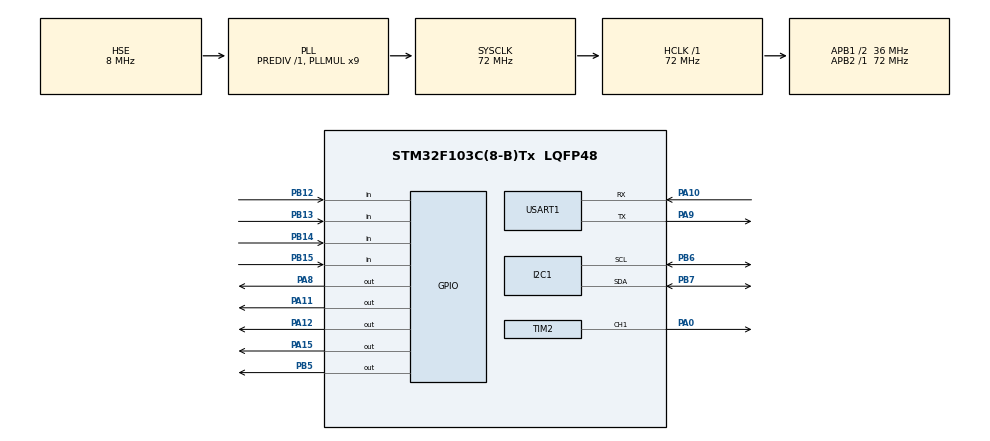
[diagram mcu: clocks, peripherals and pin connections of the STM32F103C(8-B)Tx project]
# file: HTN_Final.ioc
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FREERTOS.Tasks01=defaultTask,24,128,StartDefaultTask,Default,NULL,Dynamic,NULL,NULL
FREERTOS.configUSE_NEWLIB_REENTRANT=1
Mcu.Family=STM32F1
Mcu.Name=STM32F103C(8-B)Tx
Mcu.Package=LQFP48
NVIC.PriorityGroup=NVIC_PRIORITYGROUP_4
NVIC.TIM4_IRQn=true\:15\:0\:false\:false\:true\:false\:false\:true\:true
NVIC.TimeBase=TIM4_IRQn
NVIC.TimeBaseIP=TIM4
NVIC.USART1_IRQn=true\:5\:0\:false\:false\:true\:true\:true\:true\:true
PA0-WKUP.Signal=S_TIM2_CH1_ETR
PA10.Mode=Asynchronous
PA10.Signal=USART1_RX
PA11.Signal=GPIO_Output
PA12.Signal=GPIO_Output
PA13.Mode=Serial_Wire
PA13.Signal=SYS_JTMS-SWDIO
PA14.Mode=Serial_Wire
PA14.Signal=SYS_JTCK-SWCLK
PA15.Signal=GPIO_Output
PA8.Signal=GPIO_Output
PA9.Mode=Asynchronous
PA9.Signal=USART1_TX
PB12.GPIO_PuPd=GPIO_PULLUP
PB12.Signal=GPIO_Input
PB13.GPIO_PuPd=GPIO_PULLUP
PB13.Signal=GPIO_Input
PB14.GPIO_PuPd=GPIO_PULLUP
PB14.Signal=GPIO_Input
PB15.GPIO_PuPd=GPIO_PULLUP
PB15.Signal=GPIO_Input
PB5.Signal=GPIO_Output
PB6.Mode=I2C
PB6.Signal=I2C1_SCL
PB7.Mode=I2C
PB7.Signal=I2C1_SDA
PD0-OSC_IN.Mode=HSE-External-Oscillator
PD0-OSC_IN.Signal=RCC_OSC_IN
PD1-OSC_OUT.Mode=HSE-External-Oscillator
PD1-OSC_OUT.Signal=RCC_OSC_OUT
ProjectManager.HeapSize=0x200
ProjectManager.StackSize=0x400
ProjectManager.TargetToolchain=STM32CubeIDE
RCC.AHBFreq_Value=72000000
RCC.APB1CLKDivider=RCC_HCLK_DIV2
RCC.APB1Freq_Value=36000000
RCC.APB1TimFreq_Value=72000000
RCC.APB2Freq_Value=72000000
RCC.APB2TimFreq_Value=72000000
RCC.HCLKFreq_Value=72000000
RCC.PLLMUL=RCC_PLL_MUL9
RCC.PLLSourceVirtual=RCC_PLLSOURCE_HSE
RCC.SYSCLKFreq_VALUE=72000000
RCC.SYSCLKSource=RCC_SYSCLKSOURCE_PLLCLK
RCC.USBFreq_Value=72000000
SH.S_TIM2_CH1_ETR.0=TIM2_CH1,PWM Generation1 CH1
TIM2.Channel-PWM\ Generation1\ CH1=TIM_CHANNEL_1
TIM2.Period=19999
TIM2.Prescaler=71
USART1.VirtualMode=VM_ASYNC
VP_FREERTOS_VS_CMSIS_V2.Mode=CMSIS_V2
VP_SYS_VS_tim4.Mode=TIM4
VP_TIM2_VS_ClockSourceINT.Mode=Internal
board=custom

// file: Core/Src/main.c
/* USER CODE BEGIN Header */
/**
  ******************************************************************************
  * @file           : main.c
  * @brief          : Main program body
  ******************************************************************************
  */
/* USER CODE END Header */

#include "main.h"
#include "cmsis_os.h"

/* USER CODE BEGIN Includes */
#include "app_freertos.h"
#include "servo.h"
#include "CLCD_I2C.h"
/* USER CODE END Includes */

I2C_HandleTypeDef hi2c1;
TIM_HandleTypeDef htim2;
UART_HandleTypeDef huart1;
extern CLCD_I2C_Name LCD1;

/* Definitions for defaultTask */
osThreadId_t defaultTaskHandle;
const osThreadAttr_t defaultTask_attributes = {
  .name = "defaultTask",
  .stack_size = 128 * 4,
  .priority = (osPriority_t) osPriorityNormal,
};

void SystemClock_Config(void);
static void MX_GPIO_Init(void);
static void MX_I2C1_Init(void);
static void MX_TIM2_Init(void);
static void MX_USART1_UART_Init(void);
void StartDefaultTask(void *argument);

int main(void)
{
  /* MCU Configuration--------------------------------------------------------*/
  HAL_Init();

  /* Configure the system clock */
  SystemClock_Config();

  /* Initialize all configured peripherals */
  MX_GPIO_Init();
  MX_I2C1_Init();
  MX_TIM2_Init();
  MX_USART1_UART_Init();

  /* USER CODE BEGIN 2 */
  // Khởi tạo PWM cho Servo để chốt cửa ở trạng thái đóng khi vừa cấp điện
  Servo_Init();

  /* USER CODE END 2 */

  /* Init scheduler */
  osKernelInitialize();

  /* USER CODE BEGIN RTOS_THREADS */
  /**
   * App_Init_FreeRTOS sẽ khởi tạo Mutex, Queue và các Task.
   * Việc khởi tạo LCD sẽ được thực hiện bên trong Task_Auth để đảm bảo
   * an toàn trong môi trường đa nhiệm.
   */
  App_Init_FreeRTOS();
  /* USER CODE END RTOS_THREADS */

  /* Start scheduler */
  osKernelStart();

  /* We should never get here */
  while (1)
  {
  }
}

void SystemClock_Config(void)
{
  RCC_OscInitTypeDef RCC_OscInitStruct = {0};
  RCC_ClkInitTypeDef RCC_ClkInitStruct = {0};

  RCC_OscInitStruct.OscillatorType = RCC_OSCILLATORTYPE_HSE;
  RCC_OscInitStruct.HSEState = RCC_HSE_ON;
  RCC_OscInitStruct.HSEPredivValue = RCC_HSE_PREDIV_DIV1;
  RCC_OscInitStruct.HSIState = RCC_HSI_ON;
  RCC_OscInitStruct.PLL.PLLState = RCC_PLL_ON;
  RCC_OscInitStruct.PLL.PLLSource = RCC_PLLSOURCE_HSE;
  RCC_OscInitStruct.PLL.PLLMUL = RCC_PLL_MUL9;
  if (HAL_RCC_OscConfig(&RCC_OscInitStruct) != HAL_OK)
  {
    Error_Handler();
  }

  RCC_ClkInitStruct.ClockType = RCC_CLOCKTYPE_HCLK|RCC_CLOCKTYPE_SYSCLK
                              |RCC_CLOCKTYPE_PCLK1|RCC_CLOCKTYPE_PCLK2;
  RCC_ClkInitStruct.SYSCLKSource = RCC_SYSCLKSOURCE_PLLCLK;
  RCC_ClkInitStruct.AHBCLKDivider = RCC_SYSCLK_DIV1;
  RCC_ClkInitStruct.APB1CLKDivider = RCC_HCLK_DIV2;
  RCC_ClkInitStruct.APB2CLKDivider = RCC_HCLK_DIV1;

  if (HAL_RCC_ClockConfig(&RCC_ClkInitStruct, FLASH_LATENCY_2) != HAL_OK)
  {
    Error_Handler();
  }
}

static void MX_I2C1_Init(void)
{
  hi2c1.Instance = I2C1;
  hi2c1.Init.ClockSpeed = 100000;
  hi2c1.Init.DutyCycle = I2C_DUTYCYCLE_2;
  hi2c1.Init.OwnAddress1 = 0;
  hi2c1.Init.AddressingMode = I2C_ADDRESSINGMODE_7BIT;
  hi2c1.Init.DualAddressMode = I2C_DUALADDRESS_DISABLE;
  hi2c1.Init.OwnAddress2 = 0;
  hi2c1.Init.GeneralCallMode = I2C_GENERALCALL_DISABLE;
  hi2c1.Init.NoStretchMode = I2C_NOSTRETCH_DISABLE;
  if (HAL_I2C_Init(&hi2c1) != HAL_OK)
  {
    Error_Handler();
  }
}

static void MX_TIM2_Init(void)
{
  TIM_ClockConfigTypeDef sClockSourceConfig = {0};
  TIM_MasterConfigTypeDef sMasterConfig = {0};
  TIM_OC_InitTypeDef sConfigOC = {0};

  htim2.Instance = TIM2;
  htim2.Init.Prescaler = 71;
  htim2.Init.CounterMode = TIM_COUNTERMODE_UP;
  htim2.Init.Period = 19999;
  htim2.Init.ClockDivision = TIM_CLOCKDIVISION_DIV1;
  htim2.Init.AutoReloadPreload = TIM_AUTORELOAD_PRELOAD_DISABLE;
  if (HAL_TIM_Base_Init(&htim2) != HAL_OK)
  {
    Error_Handler();
  }
  sClockSourceConfig.ClockSource = TIM_CLOCKSOURCE_INTERNAL;
  if (HAL_TIM_ConfigClockSource(&htim2, &sClockSourceConfig) != HAL_OK)
  {
    Error_Handler();
  }
  if (HAL_TIM_PWM_Init(&htim2) != HAL_OK)
  {
    Error_Handler();
  }
  sMasterConfig.MasterOutputTrigger = TIM_TRGO_RESET;
  sMasterConfig.MasterSlaveMode = TIM_MASTERSLAVEMODE_DISABLE;
  if (HAL_TIMEx_MasterConfigSynchronization(&htim2, &sMasterConfig) != HAL_OK)
  {
    Error_Handler();
  }
  sConfigOC.OCMode = TIM_OCMODE_PWM1;
  sConfigOC.Pulse = 0;
  sConfigOC.OCPolarity = TIM_OCPOLARITY_HIGH;
  sConfigOC.OCFastMode = TIM_OCFAST_DISABLE;
  if (HAL_TIM_PWM_ConfigChannel(&htim2, &sConfigOC, TIM_CHANNEL_1) != HAL_OK)
  {
    Error_Handler();
  }
  HAL_TIM_MspPostInit(&htim2);
}

static void MX_USART1_UART_Init(void)
{
  huart1.Instance = USART1;
  huart1.Init.BaudRate = 57600;
  huart1.Init.WordLength = UART_WORDLENGTH_8B;
  huart1.Init.StopBits = UART_STOPBITS_1;
  huart1.Init.Parity = UART_PARITY_NONE;
  huart1.Init.Mode = UART_MODE_TX_RX;
  huart1.Init.HwFlowCtl = UART_HWCONTROL_NONE;
  huart1.Init.OverSampling = UART_OVERSAMPLING_16;
  if (HAL_UART_Init(&huart1) != HAL_OK)
  {
    Error_Handler();
  }
}

static void MX_GPIO_Init(void)
{
  GPIO_InitTypeDef GPIO_InitStruct = {0};

  __HAL_RCC_GPIOD_CLK_ENABLE();
  __HAL_RCC_GPIOA_CLK_ENABLE();
  __HAL_RCC_GPIOB_CLK_ENABLE();

  HAL_GPIO_WritePin(GPIOA, GPIO_PIN_8|GPIO_PIN_11|GPIO_PIN_12|GPIO_PIN_15, GPIO_PIN_RESET);
  HAL_GPIO_WritePin(GPIOB, GPIO_PIN_5, GPIO_PIN_RESET);

  GPIO_InitStruct.Pin = GPIO_PIN_12|GPIO_PIN_13|GPIO_PIN_14|GPIO_PIN_15;
  GPIO_InitStruct.Mode = GPIO_MODE_INPUT;
  GPIO_InitStruct.Pull = GPIO_PULLUP;
  HAL_GPIO_Init(GPIOB, &GPIO_InitStruct);

  GPIO_InitStruct.Pin = GPIO_PIN_8|GPIO_PIN_11|GPIO_PIN_12|GPIO_PIN_15;
  GPIO_InitStruct.Mode = GPIO_MODE_OUTPUT_PP;
  GPIO_InitStruct.Pull = GPIO_NOPULL;
  GPIO_InitStruct.Speed = GPIO_SPEED_FREQ_LOW;
  HAL_GPIO_Init(GPIOA, &GPIO_InitStruct);

  GPIO_InitStruct.Pin = GPIO_PIN_5;
  GPIO_InitStruct.Mode = GPIO_MODE_OUTPUT_PP;
  GPIO_InitStruct.Pull = GPIO_NOPULL;
  GPIO_InitStruct.Speed = GPIO_SPEED_FREQ_LOW;
  HAL_GPIO_Init(GPIOB, &GPIO_InitStruct);
}

void StartDefaultTask(void *argument)
{
  for(;;)
  {
    osDelay(1);
  }
}

void HAL_TIM_PeriodElapsedCallback(TIM_HandleTypeDef *htim)
{
  if (htim->Instance == TIM4) {
    HAL_IncTick();
  }
}

void Error_Handler(void)
{
  __disable_irq();
  while (1)
  {
  }
}

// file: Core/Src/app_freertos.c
#include "app_freertos.h"
#include "cmsis_os.h"
#include "keypad.h"
#include "as608.h"
#include "servo.h"
#include "CLCD_I2C.h"
#include <stdbool.h>
#include <string.h>

// --- THÊM DÒNG NÀY ĐỂ LẤY BIẾN I2C TỪ MAIN ---
extern I2C_HandleTypeDef hi2c1;
volatile bool isEnrolling = false;

// Các handle của FreeRTOS
osThreadId_t inputTaskHandle;
osThreadId_t authTaskHandle;
osMessageQueueId_t inputQueueHandle;
osTimerId_t autoLockTimerHandle;
osMutexId_t lcdMutexHandle;      // ← THÊM MUTEX CHO LCD

// Khai báo biến LCD toàn cục
CLCD_I2C_Name LCD1;

uint8_t error_count = 0;
const char correct_PIN[] = "1234";
char entered_PIN[10];
uint8_t pin_index = 0;

// ← THÊM MẢNG LƯU TRỮ ID ĐÃ ĐĂNG KÝ (CÓ THỂ LƯU VÀO FLASH THẬT TỪ CẢM BIẾN)
#define MAX_ENROLLED_IDS 10
uint16_t enrolledIDs[MAX_ENROLLED_IDS];
uint8_t enrolledIDCount = 0;

typedef struct {
    uint8_t dataSource;
    uint16_t value;
} InputData_t;
#define SRC_KEYPAD       0
#define SRC_FINGER       1
#define SRC_FINGER_FAIL  3
#define SRC_SYSTEM       99   //

#define EVT_AUTOLOCK     1  //

void Task_Input(void *argument);
void Task_Auth(void *argument);
void AutoLock_Callback(void *argument);

// ← HÀM HỖ TRỢ: IN LÊN LCD VỚI MUTEX
void LCD_Print(uint8_t row, uint8_t col, const char* text) {
    osMutexAcquire(lcdMutexHandle, osWaitForever);
    CLCD_I2C_SetCursor(&LCD1, row, col);
    CLCD_I2C_WriteString(&LCD1, text);
    osMutexRelease(lcdMutexHandle);
}

void LCD_Clear(void) {
    osMutexAcquire(lcdMutexHandle, osWaitForever);
    CLCD_I2C_Clear(&LCD1);
    osMutexRelease(lcdMutexHandle);
}

// ← HÀM HỖ TRỢ: KIỂM TRA ID CÓ TRONG DANH SÁCH KHÔNG
bool IsIDEnrolled(uint16_t id) {
    for (int i = 0; i < enrolledIDCount; i++) {
        if (enrolledIDs[i] == id) {
            return true;
        }
    }
    return false;
}

// ← HÀM HỖ TRỢ: THÊM ID VÀO DANH SÁCH
bool AddID(uint16_t id) {
    if (enrolledIDCount >= MAX_ENROLLED_IDS) return false;
    enrolledIDs[enrolledIDCount++] = id;
    return true;
}

// ← HÀM HỖ TRỢ: XÓA ID KHỎI DANH SÁCH
bool RemoveID(uint16_t id) {
    for (int i = 0; i < enrolledIDCount; i++) {
        if (enrolledIDs[i] == id) {
            for (int j = i; j < enrolledIDCount - 1; j++) {
                enrolledIDs[j] = enrolledIDs[j + 1];
            }
            enrolledIDCount--;
            return true;
        }
    }
    return false;
}

void App_Init_FreeRTOS(void) {
    // ← THÊM MUTEX
    const osMutexAttr_t mutex_attr = { .name = "lcdMutex" };
    lcdMutexHandle = osMutexNew(&mutex_attr);

    const osMessageQueueAttr_t q_attr = { .name = "inputQueue" };
    inputQueueHandle = osMessageQueueNew(10, sizeof(InputData_t), &q_attr);

    const osTimerAttr_t t_attr = { .name = "autoLockTimer" };
    autoLockTimerHandle = osTimerNew(AutoLock_Callback, osTimerOnce, NULL, &t_attr);

    const osThreadAttr_t input_attr = { .name = "InputTask", .stack_size = 128 * 4, .priority = osPriorityNormal };
    inputTaskHandle = osThreadNew(Task_Input, NULL, &input_attr);

    const osThreadAttr_t auth_attr = { .name = "AuthTask", .stack_size = 256 * 4, .priority = osPriorityAboveNormal };
    authTaskHandle = osThreadNew(Task_Auth, NULL, &auth_attr);
}

// --- TASK 1: QUÉT CẢM BIẾN ---
void Task_Input(void *argument) {
    InputData_t data;
    for(;;) {
        if (!isEnrolling) {
            int fingerID = AS608_CheckFingerprint();
            static int lastID = -1;

            if ((fingerID > 0) && (fingerID != lastID)) {
                data.dataSource = SRC_FINGER;
                data.value = (uint16_t)fingerID;
                osMessageQueuePut(inputQueueHandle, &data, 0, 100);
                osDelay(1000);
            }
            else if (fingerID == -1) {
                data.dataSource = SRC_FINGER_FAIL;
                data.value = 0;
                osMessageQueuePut(inputQueueHandle, &data, 0, 100);
                osDelay(1000);
            }
        }

        static char lastKey = 0;

        char key = Keypad_GetKey();
        if (key != 0 && key != lastKey) {
            data.dataSource = SRC_KEYPAD;
            data.value = key;
            osMessageQueuePut(inputQueueHandle, &data, 0, 0);
        }
        lastKey = key;
        osDelay(50);
    }
}
// --- TASK 2: XỬ LÝ CHÍNH ---
void Task_Auth(void *argument) {
    // 1. Khởi tạo LCD
    CLCD_I2C_Init(&LCD1, &hi2c1, 0x4E, 16, 2);
    LCD_Clear();
    LCD_Print(2, 0, "SMART LOCK");
    LCD_Print(3, 1, "SAN SANG...");

    InputData_t rxData;
    uint8_t systemMode = 0; // 0: Chờ chế độ, 1: Chế độ vân tay, 2: Chế độ bàn phím

    for(;;) {
        if (osMessageQueueGet(inputQueueHandle, &rxData, NULL, osWaitForever) == osOK) {
            bool unlock = false;
            if (rxData.dataSource == SRC_SYSTEM) {
                switch(rxData.value) {
                    case EVT_AUTOLOCK:
                        Lock_Close();
                        LCD_Clear();
                        LCD_Print(2,0,"DA TU KHOA");
                        osDelay(800);
                        LCD_Clear();
                        LCD_Print(2,0,"SMART LOCK");
                        LCD_Print(3,1,"SAN SANG...");
                        break;
                }
                continue;
            }
            // ← TRẠNG THÁI: CHỌN CHẾ ĐỘ (systemMode == 0)
            else if (systemMode == 0) {
                if (rxData.dataSource == 0) {
                    char key = (char)rxData.value;
                    if (key == 'A') {
                        // Chế độ vân tay
                        systemMode = 1;
                        LCD_Clear();
                        LCD_Print(1, 0, "CHE DO: VAN TAY");
                        LCD_Print(3, 1, "SAN SANG...");
                        osDelay(1500);
                        pin_index = 0;
                    }
                    else if (key == 'B') {
                        // Chế độ bàn phím
                        systemMode = 2;
                        LCD_Clear();
                        LCD_Print(0, 0, "NHAP PIN:");
                        pin_index = 0;
                    }
                    else if (key == 'C') {
                        // Chế độ quản lý vân tay
                        // ← NHẬP CHẾ ĐỘ QUẢN LÝ ID
                        LCD_Clear();
                        LCD_Print(0, 0, "QUAN LY ID:");
                        LCD_Print(1, 0, "A: Them ID");
                        LCD_Print(3, 0, "B: Xoa ID");
                        osDelay(1000);

                        char mgmtKey = 0;
                        while (mgmtKey == 0) {
                            InputData_t mgmtData;
                            if (osMessageQueueGet(inputQueueHandle, &mgmtData, NULL, 500) == osOK) {
                                if (mgmtData.dataSource == 0) {
                                    mgmtKey = (char)mgmtData.value;
                                }
                            }
                        }
                        if (mgmtKey == '*')   // ← EXIT
                                            {
                                                systemMode = 0;
                                                pin_index = 0;

                                                LCD_Clear();
                                                LCD_Print(2, 0, "SMART LOCK");
                                                LCD_Print(3, 1, "SAN SANG...");
                                                osDelay(300);
                                            }
                        else if (mgmtKey == 'A') {
                            // Thêm ID (gọi chế độ đăng ký)
                            isEnrolling = true;
                            LCD_Clear();
                            LCD_Print(0, 0, "NHAP ID(1-300):");
                            char id_str[4] = "";
                            uint8_t id_idx = 0;
                            bool cancel = false;

                            while (1) {
                                InputData_t enrollData;
                                if (osMessageQueueGet(inputQueueHandle, &enrollData, NULL, osWaitForever) == osOK) {
                                    if (enrollData.dataSource == 0) {
                                        char k = (char)enrollData.value;

                                        if (k >= '0' && k <= '9' && id_idx < 3) {
                                            id_str[id_idx++] = k;
                                            id_str[id_idx] = '\0';
                                            LCD_Print(6, 1, id_str);
                                        }
                                        else if (k == 'C') {
                                            id_idx = 0;
                                            id_str[0] = '\0';
                                            LCD_Print(6, 1, "   ");
                                        }
                                        else if (k == 'A') {
                                            cancel = true;
                                            break;
                                        }
                                        else if (k == 'D') {
                                            break;
                                        }
                                    }
                                }
                            }

                            if (!cancel && id_idx > 0) {
                                int enroll_id = 0;
                                for(int i = 0; i < id_idx; i++) {
                                    enroll_id = enroll_id * 10 + (id_str[i] - '0');
                                }

                                if (enroll_id >= 1 && enroll_id <= 300) {
                                    AS608_Enroll(enroll_id);
                                    AddID(enroll_id); // ← THÊM VÀO DANH SÁCH
                                } else {
                                    LCD_Clear();
                                    LCD_Print(0, 0, "ID KHONG HOP LE!");
                                    osDelay(2000);
                                }
                            }

                            isEnrolling = false;
                            LCD_Clear();
                            LCD_Print(2, 0, "SMART LOCK");
                            LCD_Print(3, 1, "SAN SANG...");
                            systemMode = 0;
                        }
                        else if (mgmtKey == 'B') {
                            // Xóa ID
                            LCD_Clear();
                            LCD_Print(0, 0, "NHAP ID XOA:");
                            char id_str[4] = "";
                            uint8_t id_idx = 0;

                            while (1) {
                                InputData_t enrollData;
                                if (osMessageQueueGet(inputQueueHandle, &enrollData, NULL, osWaitForever) == osOK) {
                                    if (enrollData.dataSource == 0) {
                                        char k = (char)enrollData.value;

                                        if (k >= '0' && k <= '9' && id_idx < 3) {
                                            id_str[id_idx++] = k;
                                            id_str[id_idx] = '\0';
                                            LCD_Print(6, 1, id_str);
                                        }
                                        else if (k == 'C') {
                                            id_idx = 0;
                                            id_str[0] = '\0';
                                            LCD_Print(6, 1, "   ");
                                        }
                                        else if (k == 'D') {
                                            break;
                                        }
                                    }
                                }
                            }

                            if (id_idx > 0) {
                                int delete_id = 0;
                                for(int i = 0; i < id_idx; i++) {
                                    delete_id = delete_id * 10 + (id_str[i] - '0');
                                }

                                if (RemoveID(delete_id)) {
                                    LCD_Clear();
                                    LCD_Print(1, 0, "XOA ID OK!");
                                    osDelay(1500);
                                } else {
                                    LCD_Clear();
                                    LCD_Print(0, 0, "ID KHONG TON TAI!");
                                    osDelay(1500);
                                }
                            }

                            LCD_Clear();
                            LCD_Print(2, 0, "SMART LOCK");
                            LCD_Print(3, 1, "SAN SANG...");
                            systemMode = 0;
                        }
                    }
                }
            }
            // ← TRẠNG THÁI: CHẾ ĐỘ VÂN TAY (systemMode == 1)
            else if (systemMode == 1) {
                if (rxData.dataSource == 1 && rxData.value > 0) {
                    unlock = true;
                }
                else if (rxData.dataSource == 3) {
                    LCD_Clear();
                    LCD_Print(1, 0, "VANTAY KHONG HOP");
                    osDelay(2000);
                    LCD_Clear();
                    LCD_Print(1, 0, "CHE DO: VAN TAY");
                    LCD_Print(3, 1, "SAN SANG...");
                }
                else if (rxData.dataSource == 0) {
                    char key = (char)rxData.value;
                    if (key == '*') {
                        // Quay về menu chính
                        LCD_Clear();
                        LCD_Print(2, 0, "SMART LOCK");
                        LCD_Print(3, 1, "SAN SANG...");
                        systemMode = 0;
                    }
                }

            }
            // ← TRẠNG THÁI: CHẾ ĐỘ BÀN PHÍM (systemMode == 2)
            else if (systemMode == 2) {
                if (rxData.dataSource == 0) {
                    char key = (char)rxData.value;
                    if (key == '*')   // ← EXIT
                    {
                        systemMode = 0;
                        pin_index = 0;

                        LCD_Clear();
                        LCD_Print(2, 0, "SMART LOCK");
                        LCD_Print(3, 1, "SAN SANG...");
                        osDelay(300);
                    }
                    else if (key == 'D') {
                        entered_PIN[pin_index] = '\0';
                        if (strcmp(entered_PIN, correct_PIN) == 0) {
                            unlock = true;
                        } else {
                            LCD_Clear();
                            LCD_Print(2, 0, "SAI MA PIN!");
                            osDelay(2000);
                            LCD_Clear();
                            LCD_Print(0, 0, "NHAP LAI:");
                        }
                        pin_index = 0;
                    }
                    else if (key == 'C') {
                        pin_index = 0;
                        LCD_Clear();
                        LCD_Print(0, 0, "NHAP LAI:");
                    }
                    else if (pin_index < 9) {
                        entered_PIN[pin_index++] = key;
                        LCD_Print(pin_index, 1, "*"); // Hiển thị * thay vì mật khẩu thật
                    }

                }
            }

            if (unlock) {
                LCD_Clear();
                LCD_Print(4, 0, "MO CUA");
                Lock_Open();
                osTimerStop(autoLockTimerHandle);
                if (osTimerStart(autoLockTimerHandle, 3000) != osOK) {
                    // debug ở đây
                }                systemMode = 0; // ← QUAY VỀ MENU CHÍNH
            }
        }
    }
}

// --- CALLBACK TIMER: TỰ ĐỘNG KHÓA ---
void AutoLock_Callback(void *argument)
{
    InputData_t ev;
    ev.dataSource = SRC_SYSTEM;
    ev.value = EVT_AUTOLOCK;

    if (osMessageQueuePut(inputQueueHandle, &ev, 0, 0) != osOK) {
        // queue full → mất event
    }
}
